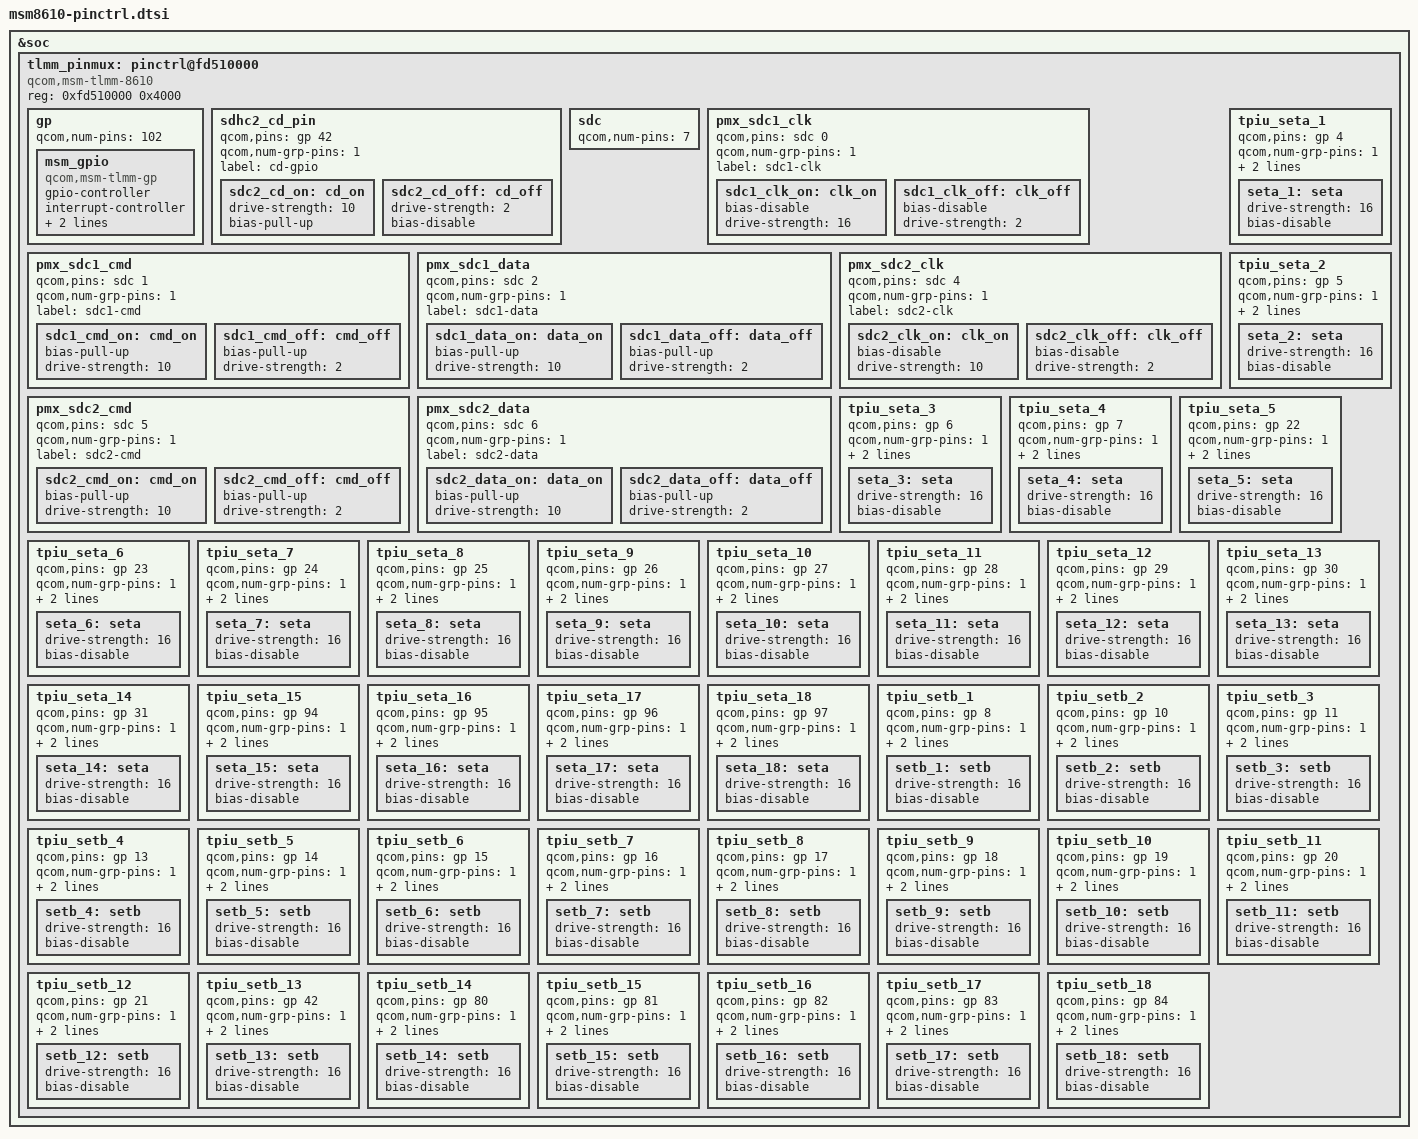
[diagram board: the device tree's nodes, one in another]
/* Copyright (c) 2013-2014, The Linux Foundation. All rights reserved.
 *
 * This program is free software; you can redistribute it and/or modify
 * it under the terms of the GNU General Public License version 2 and
 * only version 2 as published by the Free Software Foundation.
 *
 * This program is distributed in the hope that it will be useful,
 * but WITHOUT ANY WARRANTY; without even the implied warranty of
 * MERCHANTABILITY or FITNESS FOR A PARTICULAR PURPOSE.  See the
 * GNU General Public License for more details.
 */

&soc {
	tlmm_pinmux: pinctrl@fd510000 {
		compatible = "qcom,msm-tlmm-8610", "qcom,msm-tlmm-8974";
		reg = <0xfd510000 0x4000>;

		/*General purpose pins*/
		gp: gp {
			qcom,num-pins = <102>;
			#qcom,pin-cells = <1>;
			msm_gpio: msm_gpio {
				compatible = "qcom,msm-tlmm-gp";
				gpio-controller;
				#gpio-cells = <2>;
				interrupt-controller;
				interrupt-cells = <2>;
				num_irqs = <102>;
			};
		};
		/*SD card detection pin*/
		sdhc2_cd_pin {
			qcom,pins = <&gp 42>;
			qcom,num-grp-pins = <1>;
			label = "cd-gpio";
			sdc2_cd_on: cd_on {
				drive-strength = <10>;
				bias-pull-up;
			};
			sdc2_cd_off: cd_off {
				drive-strength = <2>;
				bias-disable;
			};
		};
		/* SDC pin type */
		sdc: sdc {
			/* 0-2 for sdc1 4-6 for sdc2 */
			qcom,num-pins = <7>;
			/* Order of pins */
			/* SDC1: CLK -> 0, CMD -> 1, DATA -> 2 */
			/* SDC2: CLK -> 4, CMD -> 5, DATA -> 6 */
			#qcom,pin-cells = <1>;
		};
		pmx_sdc1_clk {
			qcom,pins = <&sdc 0>;
			qcom,num-grp-pins = <1>;
			label = "sdc1-clk";
			sdc1_clk_on: clk_on {
				bias-disable; /* NO pull */
				drive-strength = <16>; /* 16 MA */
			};
			sdc1_clk_off: clk_off {
				bias-disable; /* NO pull */
				drive-strength = <2>; /* 2 MA */
			};
		};

		pmx_sdc1_cmd {
			qcom,pins = <&sdc 1>;
			qcom,num-grp-pins = <1>;
			label = "sdc1-cmd";
			sdc1_cmd_on: cmd_on {
				bias-pull-up; /* pull up */
				drive-strength = <10>; /* 10 MA */
			};
			sdc1_cmd_off: cmd_off {
				bias-pull-up; /* pull up */
				drive-strength = <2>; /* 2 MA */
			};
		};

		pmx_sdc1_data {
			qcom,pins = <&sdc 2>;
			qcom,num-grp-pins = <1>;
			label = "sdc1-data";
			sdc1_data_on: data_on {
				bias-pull-up; /* pull up */
				drive-strength = <10>; /* 10 MA */
			};
			sdc1_data_off: data_off {
				bias-pull-up; /* pull up */
				drive-strength = <2>; /* 2 MA */
			};
		};

		pmx_sdc2_clk {
			qcom,pins = <&sdc 4>;
			qcom,num-grp-pins = <1>;
			label = "sdc2-clk";
			sdc2_clk_on: clk_on {
				bias-disable; /* NO pull */
				drive-strength = <10>; /* 10 MA */
			};
			sdc2_clk_off: clk_off {
				bias-disable; /* NO pull */
				drive-strength = <2>; /* 2 MA */
			};
		};

		pmx_sdc2_cmd {
			qcom,pins = <&sdc 5>;
			qcom,num-grp-pins = <1>;
			label = "sdc2-cmd";
			sdc2_cmd_on: cmd_on {
				bias-pull-up; /* pull up */
				drive-strength = <10>; /* 10 MA */
			};
			sdc2_cmd_off: cmd_off {
				bias-pull-up; /* pull up */
				drive-strength = <2>; /* 2 MA */
			};
		};

		pmx_sdc2_data {
			qcom,pins = <&sdc 6>;
			qcom,num-grp-pins = <1>;
			label = "sdc2-data";
			sdc2_data_on: data_on {
				bias-pull-up; /* pull up */
				drive-strength = <10>; /* 10 MA */
			};
			sdc2_data_off: data_off {
				bias-pull-up; /* pull up */
				drive-strength = <2>; /* 2 MA */
			};
		};

		/* CoreSight */
		tpiu_seta_1 {
			qcom,pins = <&gp 4>;
			qcom,num-grp-pins = <1>;
			qcom,pin-func = <9>;
			label = "tpiu-seta-1";
			seta_1: seta {
				drive-strength = <16>;
				bias-disable;
			};
		};

		tpiu_seta_2 {
			qcom,pins = <&gp 5>;
			qcom,num-grp-pins = <1>;
			qcom,pin-func = <9>;
			label = "tpiu-seta-2";
			seta_2: seta {
				drive-strength = <16>;
				bias-disable;
			};
		};

		tpiu_seta_3 {
			qcom,pins = <&gp 6>;
			qcom,num-grp-pins = <1>;
			qcom,pin-func = <8>;
			label = "tpiu-seta-3";
			seta_3: seta {
				drive-strength = <16>;
				bias-disable;
			};
		};

		tpiu_seta_4 {
			qcom,pins = <&gp 7>;
			qcom,num-grp-pins = <1>;
			qcom,pin-func = <11>;
			label = "tpiu-seta-4";
			seta_4: seta {
				drive-strength = <16>;
				bias-disable;
			};
		};

		tpiu_seta_5 {
			qcom,pins = <&gp 22>;
			qcom,num-grp-pins = <1>;
			qcom,pin-func = <2>;
			label = "tpiu-seta-5";
			seta_5: seta {
				drive-strength = <16>;
				bias-disable;
			};
		};

		tpiu_seta_6 {
			qcom,pins = <&gp 23>;
			qcom,num-grp-pins = <1>;
			qcom,pin-func = <2>;
			label = "tpiu-seta-6";
			seta_6: seta {
				drive-strength = <16>;
				bias-disable;
			};
		};

		tpiu_seta_7 {
			qcom,pins = <&gp 24>;
			qcom,num-grp-pins = <1>;
			qcom,pin-func = <2>;
			label = "tpiu-seta-7";
			seta_7: seta {
				drive-strength = <16>;
				bias-disable;
			};
		};

		tpiu_seta_8 {
			qcom,pins = <&gp 25>;
			qcom,num-grp-pins = <1>;
			qcom,pin-func = <2>;
			label = "tpiu-seta-8";
			seta_8: seta {
				drive-strength = <16>;
				bias-disable;
			};
		};

		tpiu_seta_9 {
			qcom,pins = <&gp 26>;
			qcom,num-grp-pins = <1>;
			qcom,pin-func = <2>;
			label = "tpiu-seta-9";
			seta_9: seta {
				drive-strength = <16>;
				bias-disable;
			};
		};

		tpiu_seta_10 {
			qcom,pins = <&gp 27>;
			qcom,num-grp-pins = <1>;
			qcom,pin-func = <2>;
			label = "tpiu-seta-10";
			seta_10: seta {
				drive-strength = <16>;
				bias-disable;
			};
		};

		tpiu_seta_11 {
			qcom,pins = <&gp 28>;
			qcom,num-grp-pins = <1>;
			qcom,pin-func = <3>;
			label = "tpiu-seta-11";
			seta_11: seta {
				drive-strength = <16>;
				bias-disable;
			};
		};

		tpiu_seta_12 {
			qcom,pins = <&gp 29>;
			qcom,num-grp-pins = <1>;
			qcom,pin-func = <2>;
			label = "tpiu-seta-12";
			seta_12: seta {
				drive-strength = <16>;
				bias-disable;
			};
		};

		tpiu_seta_13 {
			qcom,pins = <&gp 30>;
			qcom,num-grp-pins = <1>;
			qcom,pin-func = <3>;
			label = "tpiu-seta-13";
			seta_13: seta {
				drive-strength = <16>;
				bias-disable;
			};
		};

		tpiu_seta_14 {
			qcom,pins = <&gp 31>;
			qcom,num-grp-pins = <1>;
			qcom,pin-func = <3>;
			label = "tpiu-seta-14";
			seta_14: seta {
				drive-strength = <16>;
				bias-disable;
			};
		};

		tpiu_seta_15 {
			qcom,pins = <&gp 94>;
			qcom,num-grp-pins = <1>;
			qcom,pin-func = <4>;
			label = "tpiu-seta-15";
			seta_15: seta {
				drive-strength = <16>;
				bias-disable;
			};
		};

		tpiu_seta_16 {
			qcom,pins = <&gp 95>;
			qcom,num-grp-pins = <1>;
			qcom,pin-func = <4>;
			label = "tpiu-seta-16";
			seta_16: seta {
				drive-strength = <16>;
				bias-disable;
			};
		};

		tpiu_seta_17 {
			qcom,pins = <&gp 96>;
			qcom,num-grp-pins = <1>;
			qcom,pin-func = <4>;
			label = "tpiu-seta-17";
			seta_17: seta {
				drive-strength = <16>;
				bias-disable;
			};
		};

		tpiu_seta_18 {
			qcom,pins = <&gp 97>;
			qcom,num-grp-pins = <1>;
			qcom,pin-func = <4>;
			label = "tpiu-seta-18";
			seta_18: seta {
				drive-strength = <16>;
				bias-disable;
			};
		};

		tpiu_setb_1 {
			qcom,pins = <&gp 8>;
			qcom,num-grp-pins = <1>;
			qcom,pin-func = <10>;
			label = "tpiu-setb-1";
			setb_1: setb {
				drive-strength = <16>;
				bias-disable;
			};
		};

		tpiu_setb_2 {
			qcom,pins = <&gp 10>;
			qcom,num-grp-pins = <1>;
			qcom,pin-func = <8>;
			label = "tpiu-setb-2";
			setb_2: setb {
				drive-strength = <16>;
				bias-disable;
			};
		};

		tpiu_setb_3 {
			qcom,pins = <&gp 11>;
			qcom,num-grp-pins = <1>;
			qcom,pin-func = <8>;
			label = "tpiu-setb-3";
			setb_3: setb {
				drive-strength = <16>;
				bias-disable;
			};
		};

		tpiu_setb_4 {
			qcom,pins = <&gp 13>;
			qcom,num-grp-pins = <1>;
			qcom,pin-func = <6>;
			label = "tpiu-setb-4";
			setb_4: setb {
				drive-strength = <16>;
				bias-disable;
			};
		};

		tpiu_setb_5 {
			qcom,pins = <&gp 14>;
			qcom,num-grp-pins = <1>;
			qcom,pin-func = <9>;
			label = "tpiu-setb-5";
			setb_5: setb {
				drive-strength = <16>;
				bias-disable;
			};
		};

		tpiu_setb_6 {
			qcom,pins = <&gp 15>;
			qcom,num-grp-pins = <1>;
			qcom,pin-func = <9>;
			label = "tpiu-setb-6";
			setb_6: setb {
				drive-strength = <16>;
				bias-disable;
			};
		};

		tpiu_setb_7 {
			qcom,pins = <&gp 16>;
			qcom,num-grp-pins = <1>;
			qcom,pin-func = <9>;
			label = "tpiu-setb-7";
			setb_7: setb {
				drive-strength = <16>;
				bias-disable;
			};
		};

		tpiu_setb_8 {
			qcom,pins = <&gp 17>;
			qcom,num-grp-pins = <1>;
			qcom,pin-func = <9>;
			label = "tpiu-setb-8";
			setb_8: setb {
				drive-strength = <16>;
				bias-disable;
			};
		};

		tpiu_setb_9 {
			qcom,pins = <&gp 18>;
			qcom,num-grp-pins = <1>;
			qcom,pin-func = <9>;
			label = "tpiu-setb-9";
			setb_9: setb {
				drive-strength = <16>;
				bias-disable;
			};
		};

		tpiu_setb_10 {
			qcom,pins = <&gp 19>;
			qcom,num-grp-pins = <1>;
			qcom,pin-func = <9>;
			label = "tpiu-setb-10";
			setb_10: setb {
				drive-strength = <16>;
				bias-disable;
			};
		};

		tpiu_setb_11 {
			qcom,pins = <&gp 20>;
			qcom,num-grp-pins = <1>;
			qcom,pin-func = <9>;
			label = "tpiu-setb-11";
			setb_11: setb {
				drive-strength = <16>;
				bias-disable;
			};
		};

		tpiu_setb_12 {
			qcom,pins = <&gp 21>;
			qcom,num-grp-pins = <1>;
			qcom,pin-func = <9>;
			label = "tpiu-setb-12";
			setb_12: setb {
				drive-strength = <16>;
				bias-disable;
			};
		};

		tpiu_setb_13 {
			qcom,pins = <&gp 42>;
			qcom,num-grp-pins = <1>;
			qcom,pin-func = <5>;
			label = "tpiu-setb-13";
			setb_13: setb {
				drive-strength = <16>;
				bias-disable;
			};
		};

		tpiu_setb_14 {
			qcom,pins = <&gp 80>;
			qcom,num-grp-pins = <1>;
			qcom,pin-func = <7>;
			label = "tpiu-setb-14";
			setb_14: setb {
				drive-strength = <16>;
				bias-disable;
			};
		};

		tpiu_setb_15 {
			qcom,pins = <&gp 81>;
			qcom,num-grp-pins = <1>;
			qcom,pin-func = <7>;
			label = "tpiu-setb-15";
			setb_15: setb {
				drive-strength = <16>;
				bias-disable;
			};
		};

		tpiu_setb_16 {
			qcom,pins = <&gp 82>;
			qcom,num-grp-pins = <1>;
			qcom,pin-func = <8>;
			label = "tpiu-setb-16";
			setb_16: setb {
				drive-strength = <16>;
				bias-disable;
			};
		};

		tpiu_setb_17 {
			qcom,pins = <&gp 83>;
			qcom,num-grp-pins = <1>;
			qcom,pin-func = <8>;
			label = "tpiu-setb-17";
			setb_17: setb {
				drive-strength = <16>;
				bias-disable;
			};
		};

		tpiu_setb_18 {
			qcom,pins = <&gp 84>;
			qcom,num-grp-pins = <1>;
			qcom,pin-func = <8>;
			label = "tpiu-setb-18";
			setb_18: setb {
				drive-strength = <16>;
				bias-disable;
			};
		};
	};
};
